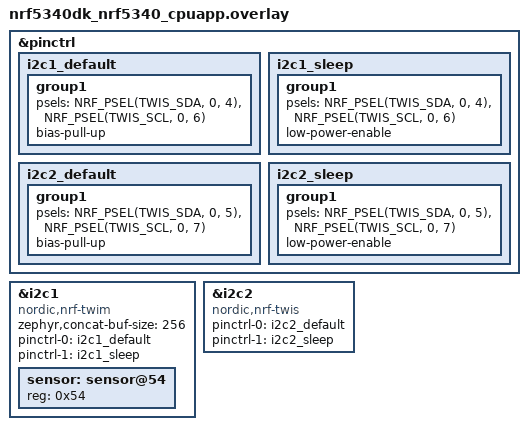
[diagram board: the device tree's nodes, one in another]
/*
 * Copyright (c) 2026 Nordic Semiconductor ASA
 *
 * SPDX-License-Identifier: Apache-2.0
 */

&pinctrl {
	i2c1_default: i2c1_default {
		group1 {
			psels = <NRF_PSEL(TWIS_SDA, 0, 4)>,
				<NRF_PSEL(TWIS_SCL, 0, 6)>;
			bias-pull-up;
		};
	};

	i2c1_sleep: i2c1_sleep {
		group1 {
			psels = <NRF_PSEL(TWIS_SDA, 0, 4)>,
				<NRF_PSEL(TWIS_SCL, 0, 6)>;
			low-power-enable;
		};
	};

	i2c2_default: i2c2_default {
		group1 {
			psels = <NRF_PSEL(TWIS_SDA, 0, 5)>,
				<NRF_PSEL(TWIS_SCL, 0, 7)>;
			bias-pull-up;
		};
	};

	i2c2_sleep: i2c2_sleep {
		group1 {
			psels = <NRF_PSEL(TWIS_SDA, 0, 5)>,
				<NRF_PSEL(TWIS_SCL, 0, 7)>;
			low-power-enable;
		};
	};
};

dut_twim: &i2c1 {
	compatible = "nordic,nrf-twim";
	status = "okay";
	zephyr,concat-buf-size = <256>;
	pinctrl-0 = <&i2c1_default>;
	pinctrl-1 = <&i2c1_sleep>;
	pinctrl-names = "default", "sleep";

	sensor: sensor@54 {
		reg = <0x54>;
	};
};

dut_twis: &i2c2 {
	compatible = "nordic,nrf-twis";
	status = "okay";
	pinctrl-0 = <&i2c2_default>;
	pinctrl-1 = <&i2c2_sleep>;
	pinctrl-names = "default", "sleep";
};
